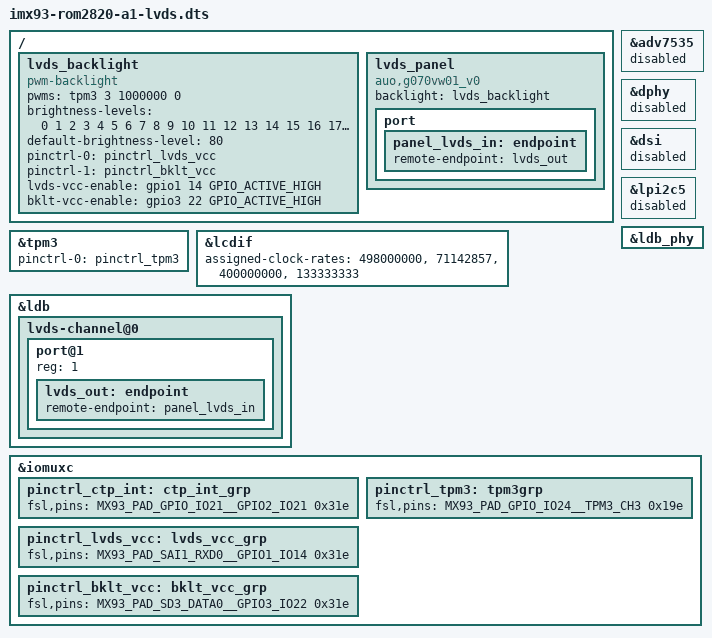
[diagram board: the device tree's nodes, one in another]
// SPDX-License-Identifier: (GPL-2.0+ OR MIT)
/*
 * Copyright 2022 NXP
 */

#include "imx93-rom2820-a1.dts"

/ {
	lvds_backlight: lvds_backlight {
		compatible = "pwm-backlight";
		pwms = <&tpm3 3 1000000 0>;
		status = "okay";

		brightness-levels = < 0  1  2  3  4  5  6  7  8  9
				     10 11 12 13 14 15 16 17 18 19
				     20 21 22 23 24 25 26 27 28 29
				     30 31 32 33 34 35 36 37 38 39
				     40 41 42 43 44 45 46 47 48 49
				     50 51 52 53 54 55 56 57 58 59
				     60 61 62 63 64 65 66 67 68 69
				     70 71 72 73 74 75 76 77 78 79
				     80 81 82 83 84 85 86 87 88 89
				     90 91 92 93 94 95 96 97 98 99
				    100>;
		default-brightness-level = <80>;
	};

	lvds_panel {
		compatible = "auo,g070vw01_v0";
		backlight = <&lvds_backlight>;

		port {
			panel_lvds_in: endpoint {
				remote-endpoint = <&lvds_out>;
			};
		};
	};
};

&tpm3 {
        pinctrl-names = "default";
        pinctrl-0 = <&pinctrl_tpm3>;
        status = "okay";
};

&adv7535 {
	status = "disabled";
};

&dphy {
	status = "disabled";
};

&dsi {
	status = "disabled";
};

&lpi2c5 {
        status = "disabled";
};

&lcdif {
	assigned-clock-rates = <498000000>, <71142857>, <400000000>, <133333333>;
};

&ldb {
	status = "okay";

	lvds-channel@0 {
		status = "okay";

		port@1 {
			reg = <1>;

			lvds_out: endpoint {
				remote-endpoint = <&panel_lvds_in>;
			};
		};
	};
};

&ldb_phy {
	status = "okay";
};

&lvds_backlight {
	pinctrl-names = "default";
	pinctrl-0 = <&pinctrl_lvds_vcc>;
	pinctrl-1 = <&pinctrl_bklt_vcc>;
	lvds-vcc-enable = <&gpio1 14 GPIO_ACTIVE_HIGH>;	/* LCD_VDD_EN */
	bklt-vcc-enable = <&gpio3 22 GPIO_ACTIVE_HIGH>;	/* LVDS_BL_EN */
	status = "okay";
};

&iomuxc {
	pinctrl_ctp_int: ctp_int_grp {
		fsl,pins = <
			MX93_PAD_GPIO_IO21__GPIO2_IO21          0x31e
		>;
	};

	pinctrl_tpm3: tpm3grp {
                fsl,pins = <
                        MX93_PAD_GPIO_IO24__TPM3_CH3		0x19e
                >;
        };

	pinctrl_lvds_vcc: lvds_vcc_grp {
                fsl,pins = <
                        MX93_PAD_SAI1_RXD0__GPIO1_IO14          0x31e
                >;
        };

	pinctrl_bklt_vcc: bklt_vcc_grp {
                fsl,pins = <
                        MX93_PAD_SD3_DATA0__GPIO3_IO22          0x31e
                >;
        };
};
